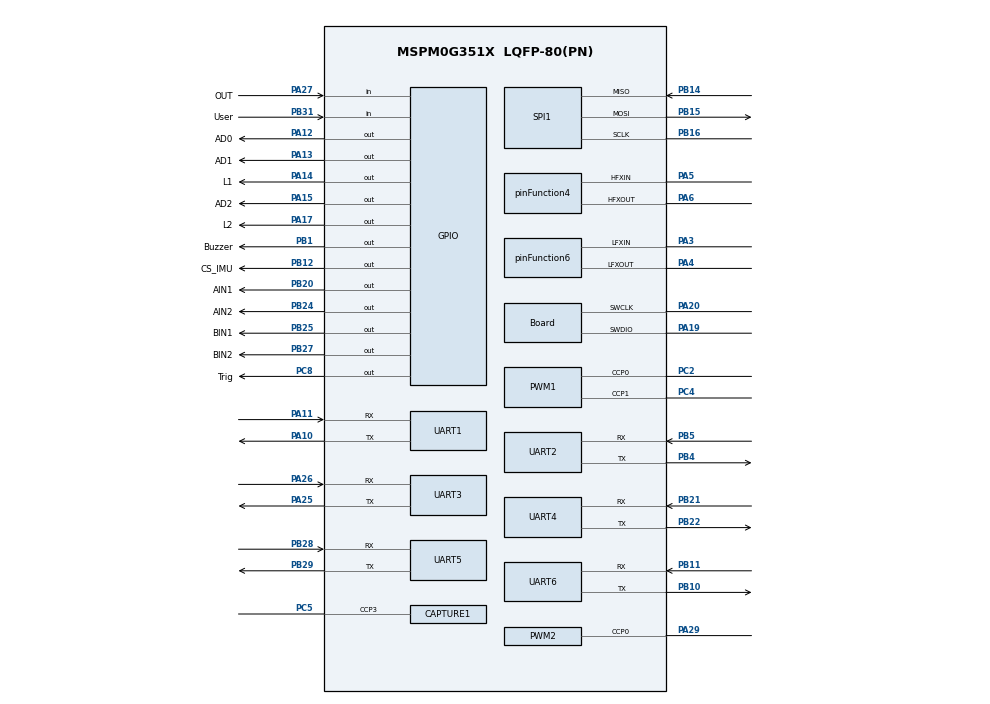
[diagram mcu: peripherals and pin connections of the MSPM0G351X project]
/**
 *
 * @cliArgs --device "MSPM0G351X" --part "Default" --package "LQFP-80(PN)" --product "mspm0_sdk@2.11.00.07"
 * @versions {"tool":"1.28.0+4712"}
 */

/**
 * Import the modules used in this configuration.
 */
const CAPTURE  = scripting.addModule("/ti/driverlib/CAPTURE", {}, false);
const CAPTURE1 = CAPTURE.addInstance();
const DMA      = scripting.addModule("/ti/driverlib/DMA");
const GPIO     = scripting.addModule("/ti/driverlib/GPIO", {}, false);
const GPIO1    = GPIO.addInstance();
const GPIO2    = GPIO.addInstance();
const GPIO3    = GPIO.addInstance();
const GPIO4    = GPIO.addInstance();
const GPIO5    = GPIO.addInstance();
const GPIO6    = GPIO.addInstance();
const GPIO7    = GPIO.addInstance();
const GPIO8    = GPIO.addInstance();
const PWM      = scripting.addModule("/ti/driverlib/PWM", {}, false);
const PWM1     = PWM.addInstance();
const PWM2     = PWM.addInstance();
const SPI      = scripting.addModule("/ti/driverlib/SPI", {}, false);
const SPI1     = SPI.addInstance();
const SYSCTL   = scripting.addModule("/ti/driverlib/SYSCTL");
const TIMER    = scripting.addModule("/ti/driverlib/TIMER", {}, false);
const TIMER1   = TIMER.addInstance();
const UART     = scripting.addModule("/ti/driverlib/UART", {}, false);
const UART1    = UART.addInstance();
const UART2    = UART.addInstance();
const UART3    = UART.addInstance();
const UART4    = UART.addInstance();
const UART5    = UART.addInstance();
const UART6    = UART.addInstance();

/**
 * Write custom configuration values to the imported modules.
 */
const divider2       = system.clockTree["HFCLK4MFPCLKDIV"];
divider2.divideValue = 10;

const divider9       = system.clockTree["UDIV"];
divider9.divideValue = 2;

const gate7  = system.clockTree["MFCLKGATE"];
gate7.enable = true;

const gate8  = system.clockTree["MFPCLKGATE"];
gate8.enable = true;

const multiplier2         = system.clockTree["PLL_QDIV"];
multiplier2.multiplyValue = 4;

const mux4       = system.clockTree["EXHFMUX"];
mux4.inputSelect = "EXHFMUX_XTAL";

const mux8       = system.clockTree["HSCLKMUX"];
mux8.inputSelect = "HSCLKMUX_SYSPLL0";

const mux10       = system.clockTree["MFPCLKMUX"];
mux10.inputSelect = "MFPCLKMUX_HFCLK";

const mux12       = system.clockTree["SYSPLLMUX"];
mux12.inputSelect = "zSYSPLLMUX_HFCLK";

const pinFunction4                        = system.clockTree["HFXT"];
pinFunction4.inputFreq                    = 40;
pinFunction4.enable                       = true;
pinFunction4.HFXTStartup                  = 100;
pinFunction4.peripheral.$assign           = "SYSCTL";
pinFunction4.peripheral.hfxInPin.$assign  = "PA5";
pinFunction4.peripheral.hfxOutPin.$assign = "PA6";

const pinFunction6                        = system.clockTree["LFXT"];
pinFunction6.enable                       = true;
pinFunction6.inputFreq                    = 32.768;
pinFunction6.peripheral.$assign           = "SYSCTL";
pinFunction6.peripheral.lfxInPin.$assign  = "PA3";
pinFunction6.peripheral.lfxOutPin.$assign = "PA4";

CAPTURE1.$name                      = "CAPTURE_WAVE";
CAPTURE1.ccIndex                    = 3;
CAPTURE1.timerClkDiv                = 8;
CAPTURE1.timerClkPrescale           = 5;
CAPTURE1.timerPeriod                = "60 ms";
CAPTURE1.captMode                   = "PULSE_WIDTH_UP";
CAPTURE1.timerStartTimer            = true;
CAPTURE1.interrupts                 = ["CC3_UP"];
CAPTURE1.peripheral.$assign         = "TIMG14";
CAPTURE1.peripheral.ccp3Pin.$assign = "PC5";
CAPTURE1.ccp3PinConfig.$name        = "ti_driverlib_gpio_GPIOPinGeneric22";

const Board                       = scripting.addModule("/ti/driverlib/Board", {}, false);
Board.peripheral.$assign          = "DEBUGSS";
Board.peripheral.swclkPin.$assign = "PA20";
Board.peripheral.swdioPin.$assign = "PA19";

DMA.subscriberIndex                          = ["0"];
DMA.sub0ChanID                               = 1;
DMA.associatedChannels.create(1);
DMA.associatedChannels[0].$name              = "DMA_CH0";
DMA.associatedChannels[0].triggerSelect      = "FSUB_0";
DMA.associatedChannels[0].addressMode        = "b2f";
DMA.associatedChannels[0].enableInterrupt    = true;
DMA.associatedChannels[0].interruptPriority  = "2";
DMA.associatedChannels[0].peripheral.$assign = "DMA_CH0";

GPIO1.$name                              = "LED";
GPIO1.associatedPins.create(2);
GPIO1.associatedPins[0].$name            = "L1";
GPIO1.associatedPins[0].internalResistor = "PULL_UP";
GPIO1.associatedPins[0].initialValue     = "SET";
GPIO1.associatedPins[0].pin.$assign      = "PA14";
GPIO1.associatedPins[1].$name            = "L2";
GPIO1.associatedPins[1].internalResistor = "PULL_UP";
GPIO1.associatedPins[1].pin.$assign      = "PA17";

GPIO2.$name                         = "AIN";
GPIO2.associatedPins.create(2);
GPIO2.associatedPins[0].$name       = "AIN1";
GPIO2.associatedPins[0].pin.$assign = "PB20";
GPIO2.associatedPins[1].$name       = "AIN2";
GPIO2.associatedPins[1].pin.$assign = "PB24";

GPIO3.$name                         = "BIN";
GPIO3.associatedPins.create(2);
GPIO3.associatedPins[0].$name       = "BIN1";
GPIO3.associatedPins[0].pin.$assign = "PB25";
GPIO3.associatedPins[1].$name       = "BIN2";
GPIO3.associatedPins[1].pin.$assign = "PB27";

GPIO4.$name                              = "IMU";
GPIO4.associatedPins[0].initialValue     = "SET";
GPIO4.associatedPins[0].internalResistor = "PULL_UP";
GPIO4.associatedPins[0].$name            = "CS_IMU";
GPIO4.associatedPins[0].pin.$assign      = "PB12";

GPIO5.$name                         = "BUZZER";
GPIO5.associatedPins[0].$name       = "Buzzer";
GPIO5.associatedPins[0].pin.$assign = "PB1";

GPIO6.$name                         = "GREY";
GPIO6.associatedPins.create(4);
GPIO6.associatedPins[0].$name       = "OUT";
GPIO6.associatedPins[0].direction   = "INPUT";
GPIO6.associatedPins[0].pin.$assign = "PA27";
GPIO6.associatedPins[1].$name       = "AD0";
GPIO6.associatedPins[1].pin.$assign = "PA12";
GPIO6.associatedPins[2].$name       = "AD1";
GPIO6.associatedPins[2].pin.$assign = "PA13";
GPIO6.associatedPins[3].$name       = "AD2";
GPIO6.associatedPins[3].pin.$assign = "PA15";

GPIO7.$name                              = "KEY";
GPIO7.associatedPins[0].$name            = "User";
GPIO7.associatedPins[0].direction        = "INPUT";
GPIO7.associatedPins[0].internalResistor = "PULL_UP";
GPIO7.associatedPins[0].pin.$assign      = "PB31";

GPIO8.$name                         = "WAVE";
GPIO8.associatedPins[0].$name       = "Trig";
GPIO8.associatedPins[0].pin.$assign = "PC8";

PWM1.timerStartTimer                    = true;
PWM1.timerCount                         = 800;
PWM1.$name                              = "PWM_Motor";
PWM1.peripheral.$assign                 = "TIMA0";
PWM1.peripheral.ccp0Pin.$assign         = "PC2";
PWM1.peripheral.ccp1Pin.$assign         = "PC4";
PWM1.PWM_CHANNEL_0.$name                = "ti_driverlib_pwm_PWMTimerCC0";
PWM1.PWM_CHANNEL_1.$name                = "ti_driverlib_pwm_PWMTimerCC1";
PWM1.ccp0PinConfig.direction            = scripting.forceWrite("OUTPUT");
PWM1.ccp0PinConfig.hideOutputInversion  = scripting.forceWrite(false);
PWM1.ccp0PinConfig.onlyInternalResistor = scripting.forceWrite(false);
PWM1.ccp0PinConfig.passedPeripheralType = scripting.forceWrite("Digital");
PWM1.ccp0PinConfig.$name                = "ti_driverlib_gpio_GPIOPinGeneric14";
PWM1.ccp1PinConfig.direction            = scripting.forceWrite("OUTPUT");
PWM1.ccp1PinConfig.hideOutputInversion  = scripting.forceWrite(false);
PWM1.ccp1PinConfig.onlyInternalResistor = scripting.forceWrite(false);
PWM1.ccp1PinConfig.passedPeripheralType = scripting.forceWrite("Digital");
PWM1.ccp1PinConfig.$name                = "ti_driverlib_gpio_GPIOPinGeneric15";

PWM2.$name                              = "PWM_RGB";
PWM2.timerCount                         = 100;
PWM2.ccIndex                            = [0];
PWM2.event1PublisherChannel             = 1;
PWM2.event1ControllerInterruptEn        = ["LOAD_EVENT"];
PWM2.PWM_CHANNEL_0.$name                = "ti_driverlib_pwm_PWMTimerCC2";
PWM2.PWM_CHANNEL_0.dutyCycle            = 50;
PWM2.ccp0PinConfig.direction            = scripting.forceWrite("OUTPUT");
PWM2.ccp0PinConfig.hideOutputInversion  = scripting.forceWrite(false);
PWM2.ccp0PinConfig.onlyInternalResistor = scripting.forceWrite(false);
PWM2.ccp0PinConfig.passedPeripheralType = scripting.forceWrite("Digital");
PWM2.ccp0PinConfig.$name                = "ti_driverlib_gpio_GPIOPinGeneric10";
PWM2.peripheral.$assign                 = "TIMG6";
PWM2.peripheral.ccp0Pin.$assign         = "PA29";

SPI1.$name                              = "SPI_IMU";
SPI1.targetBitRate                      = 20000000;
SPI1.frameFormat                        = "MOTO3";
SPI1.polarity                           = "1";
SPI1.phase                              = "1";
SPI1.sclkPinConfig.direction            = scripting.forceWrite("OUTPUT");
SPI1.sclkPinConfig.onlyInternalResistor = scripting.forceWrite(false);
SPI1.sclkPinConfig.passedPeripheralType = scripting.forceWrite("Digital");
SPI1.sclkPinConfig.$name                = "ti_driverlib_gpio_GPIOPinGeneric11";
SPI1.mosiPinConfig.direction            = scripting.forceWrite("OUTPUT");
SPI1.mosiPinConfig.hideOutputInversion  = scripting.forceWrite(false);
SPI1.mosiPinConfig.onlyInternalResistor = scripting.forceWrite(false);
SPI1.mosiPinConfig.passedPeripheralType = scripting.forceWrite("Digital");
SPI1.mosiPinConfig.$name                = "ti_driverlib_gpio_GPIOPinGeneric12";
SPI1.misoPinConfig.onlyInternalResistor = scripting.forceWrite(false);
SPI1.misoPinConfig.passedPeripheralType = scripting.forceWrite("Digital");
SPI1.misoPinConfig.$name                = "ti_driverlib_gpio_GPIOPinGeneric21";
SPI1.peripheral.$assign                 = "SPI1";
SPI1.peripheral.sclkPin.$assign         = "PB16";
SPI1.peripheral.mosiPin.$assign         = "PB15";
SPI1.peripheral.misoPin.$assign         = "PB14";

SYSCTL.forceDefaultClkConfig = true;
SYSCTL.clockTreeEn           = true;

TIMER1.$name              = "TIMER_Clock";
TIMER1.timerMode          = "PERIODIC_UP";
TIMER1.timerStartTimer    = true;
TIMER1.interrupts         = ["LOAD"];
TIMER1.timerClkDiv        = 8;
TIMER1.timerClkPrescale   = 100;
TIMER1.timerPeriod        = "100us";
TIMER1.peripheral.$assign = "TIMA1";

UART1.$name                    = "UART_0";
UART1.targetBaudRate           = 115200;
UART1.enableFIFO               = true;
UART1.rxFifoThreshold          = "DL_UART_RX_FIFO_LEVEL_ONE_ENTRY";
UART1.enableDMARX              = false;
UART1.enableDMATX              = false;
UART1.peripheral.$assign       = "UART0";
UART1.peripheral.rxPin.$assign = "PA11";
UART1.peripheral.txPin.$assign = "PA10";
UART1.txPinConfig.$name        = "ti_driverlib_gpio_GPIOPinGeneric0";
UART1.rxPinConfig.$name        = "ti_driverlib_gpio_GPIOPinGeneric1";

UART2.targetBaudRate                   = 115200;
UART2.enabledInterrupts                = ["RX"];
UART2.interruptPriority                = "1";
UART2.$name                            = "UART_Screen";
UART2.peripheral.$assign               = "UART1";
UART2.peripheral.rxPin.$assign         = "PB5";
UART2.peripheral.txPin.$assign         = "PB4";
UART2.txPinConfig.direction            = scripting.forceWrite("OUTPUT");
UART2.txPinConfig.hideOutputInversion  = scripting.forceWrite(false);
UART2.txPinConfig.onlyInternalResistor = scripting.forceWrite(false);
UART2.txPinConfig.passedPeripheralType = scripting.forceWrite("Digital");
UART2.txPinConfig.$name                = "ti_driverlib_gpio_GPIOPinGeneric2";
UART2.rxPinConfig.hideOutputInversion  = scripting.forceWrite(false);
UART2.rxPinConfig.onlyInternalResistor = scripting.forceWrite(false);
UART2.rxPinConfig.passedPeripheralType = scripting.forceWrite("Digital");
UART2.rxPinConfig.$name                = "ti_driverlib_gpio_GPIOPinGeneric3";

UART3.targetBaudRate                   = 115200;
UART3.$name                            = "UART_Machine";
UART3.peripheral.$assign               = "UART3";
UART3.peripheral.rxPin.$assign         = "PA26";
UART3.peripheral.txPin.$assign         = "PA25";
UART3.txPinConfig.direction            = scripting.forceWrite("OUTPUT");
UART3.txPinConfig.hideOutputInversion  = scripting.forceWrite(false);
UART3.txPinConfig.onlyInternalResistor = scripting.forceWrite(false);
UART3.txPinConfig.passedPeripheralType = scripting.forceWrite("Digital");
UART3.txPinConfig.$name                = "ti_driverlib_gpio_GPIOPinGeneric6";
UART3.rxPinConfig.hideOutputInversion  = scripting.forceWrite(false);
UART3.rxPinConfig.onlyInternalResistor = scripting.forceWrite(false);
UART3.rxPinConfig.passedPeripheralType = scripting.forceWrite("Digital");
UART3.rxPinConfig.$name                = "ti_driverlib_gpio_GPIOPinGeneric7";

UART4.$name                            = "UART_JY901S";
UART4.targetBaudRate                   = 115200;
UART4.enabledInterrupts                = ["RX"];
UART4.interruptPriority                = "1";
UART4.peripheral.$assign               = "UART6";
UART4.peripheral.rxPin.$assign         = "PB21";
UART4.peripheral.txPin.$assign         = "PB22";
UART4.txPinConfig.direction            = scripting.forceWrite("OUTPUT");
UART4.txPinConfig.hideOutputInversion  = scripting.forceWrite(false);
UART4.txPinConfig.onlyInternalResistor = scripting.forceWrite(false);
UART4.txPinConfig.passedPeripheralType = scripting.forceWrite("Digital");
UART4.txPinConfig.$name                = "ti_driverlib_gpio_GPIOPinGeneric8";
UART4.rxPinConfig.hideOutputInversion  = scripting.forceWrite(false);
UART4.rxPinConfig.onlyInternalResistor = scripting.forceWrite(false);
UART4.rxPinConfig.passedPeripheralType = scripting.forceWrite("Digital");
UART4.rxPinConfig.$name                = "ti_driverlib_gpio_GPIOPinGeneric9";

UART5.$name                            = "UART_Maixcam";
UART5.enabledInterrupts                = ["RX"];
UART5.interruptPriority                = "0";
UART5.peripheral.$assign               = "UART5";
UART5.peripheral.rxPin.$assign         = "PB28";
UART5.peripheral.txPin.$assign         = "PB29";
UART5.txPinConfig.direction            = scripting.forceWrite("OUTPUT");
UART5.txPinConfig.hideOutputInversion  = scripting.forceWrite(false);
UART5.txPinConfig.onlyInternalResistor = scripting.forceWrite(false);
UART5.txPinConfig.passedPeripheralType = scripting.forceWrite("Digital");
UART5.txPinConfig.$name                = "ti_driverlib_gpio_GPIOPinGeneric13";
UART5.rxPinConfig.hideOutputInversion  = scripting.forceWrite(false);
UART5.rxPinConfig.onlyInternalResistor = scripting.forceWrite(false);
UART5.rxPinConfig.passedPeripheralType = scripting.forceWrite("Digital");
UART5.rxPinConfig.$name                = "ti_driverlib_gpio_GPIOPinGeneric20";

UART6.$name                            = "UART_Bluetooth";
UART6.peripheral.$assign               = "UART4";
UART6.peripheral.rxPin.$assign         = "PB11";
UART6.peripheral.txPin.$assign         = "PB10";
UART6.txPinConfig.direction            = scripting.forceWrite("OUTPUT");
UART6.txPinConfig.hideOutputInversion  = scripting.forceWrite(false);
UART6.txPinConfig.onlyInternalResistor = scripting.forceWrite(false);
UART6.txPinConfig.passedPeripheralType = scripting.forceWrite("Digital");
UART6.txPinConfig.$name                = "ti_driverlib_gpio_GPIOPinGeneric4";
UART6.rxPinConfig.hideOutputInversion  = scripting.forceWrite(false);
UART6.rxPinConfig.onlyInternalResistor = scripting.forceWrite(false);
UART6.rxPinConfig.passedPeripheralType = scripting.forceWrite("Digital");
UART6.rxPinConfig.$name                = "ti_driverlib_gpio_GPIOPinGeneric5";

const ProjectConfig              = scripting.addModule("/ti/project_config/ProjectConfig", {}, false);
ProjectConfig.migrationCondition = true;
